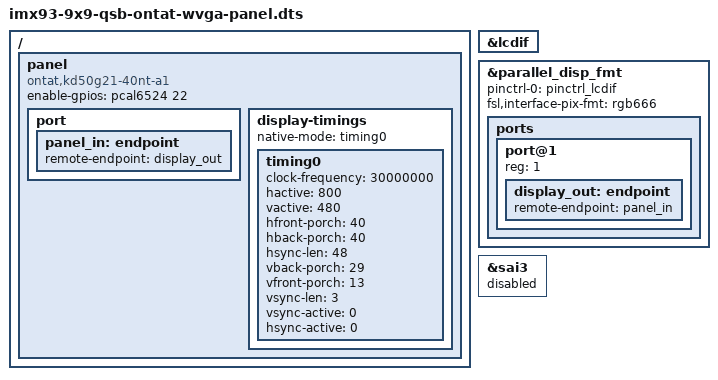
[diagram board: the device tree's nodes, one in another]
// SPDX-License-Identifier: (GPL-2.0+ OR MIT)
/*
 * Copyright 2022 NXP
 */

#include "imx93-9x9-qsb.dts"
#include "imx93-9x9-qsb-u-boot.dtsi"

/ {
	panel {
		compatible = "ontat,kd50g21-40nt-a1", "simple-panel";
		enable-gpios = <&pcal6524 22 GPIO_ACTIVE_HIGH>;

		port {
			panel_in: endpoint {
				remote-endpoint = <&display_out>;
			};
		};

		display-timings {
			native-mode = <&timing0>;
			timing0: timing0 {
				clock-frequency = <30000000>;
				hactive = <800>;
				vactive = <480>;
				hfront-porch = <40>;
				hback-porch = <40>;
				hsync-len = <48>;
				vback-porch = <29>;
				vfront-porch = <13>;
				vsync-len = <3>;

				vsync-active = <0>;
				hsync-active = <0>;
			};
		};
	};
};

&lcdif {
	status = "okay";
	/*assigned-clock-rates = <150000000>, <30000000>, <400000000>, <133333333>;*/
};

&parallel_disp_fmt {
	pinctrl-names = "default";
	pinctrl-0 = <&pinctrl_lcdif>;
	fsl,interface-pix-fmt = "rgb666";
	status = "okay";

	ports {
		port@1 {
			reg = <1>;

			display_out: endpoint {
				remote-endpoint = <&panel_in>;
			};
		};
	};
};

/* pin conflicts */
&sai3 {
	status = "disabled";
};
